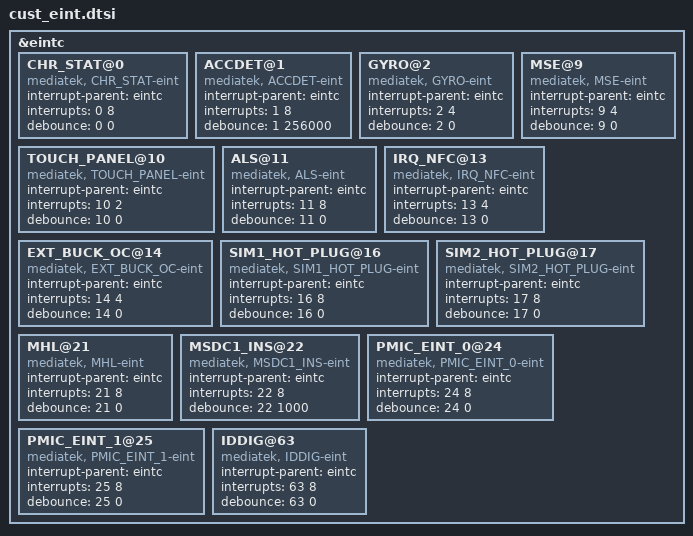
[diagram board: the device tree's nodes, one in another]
/*
 * Generated by MTK SP Drv_CodeGen Version 03.13.6  for MT6752. Copyright MediaTek Inc. (C) 2013.
 * Fri Jul 11 13:05:51 2014
 * Do Not Modify the File.
 */

/*************************
 * EINT DTSI File
*************************/

&eintc {
	CHR_STAT@0 {
		compatible = "mediatek, CHR_STAT-eint";
		interrupt-parent = <&eintc>;
		interrupts = <0 8>;
		debounce = <0 0>;
	};

	ACCDET@1 {
		compatible = "mediatek, ACCDET-eint";
		interrupt-parent = <&eintc>;
		interrupts = <1 8>;
		debounce = <1 256000>;
	};

	GYRO@2 {
		compatible = "mediatek, GYRO-eint";
		interrupt-parent = <&eintc>;
		interrupts = <2 4>;
		debounce = <2 0>;
	};

	MSE@9 {
		compatible = "mediatek, MSE-eint";
		interrupt-parent = <&eintc>;
		interrupts = <9 4>;
		debounce = <9 0>;
	};

	TOUCH_PANEL@10 {
		compatible = "mediatek, TOUCH_PANEL-eint";
		interrupt-parent = <&eintc>;
		interrupts = <10 2>;
		debounce = <10 0>;
	};

	ALS@11 {
		compatible = "mediatek, ALS-eint";
		interrupt-parent = <&eintc>;
		interrupts = <11 8>;
		debounce = <11 0>;
	};

	IRQ_NFC@13 {
		compatible = "mediatek, IRQ_NFC-eint";
		interrupt-parent = <&eintc>;
		interrupts = <13 4>;
		debounce = <13 0>;
	};

	EXT_BUCK_OC@14 {
		compatible = "mediatek, EXT_BUCK_OC-eint";
		interrupt-parent = <&eintc>;
		interrupts = <14 4>;
		debounce = <14 0>;
	};

	SIM1_HOT_PLUG@16 {
		compatible = "mediatek, SIM1_HOT_PLUG-eint";
		interrupt-parent = <&eintc>;
		interrupts = <16 8>;
		debounce = <16 0>;
	};

	SIM2_HOT_PLUG@17 {
		compatible = "mediatek, SIM2_HOT_PLUG-eint";
		interrupt-parent = <&eintc>;
		interrupts = <17 8>;
		debounce = <17 0>;
	};

	MHL@21 {
		compatible = "mediatek, MHL-eint";
		interrupt-parent = <&eintc>;
		interrupts = <21 8>;
		debounce = <21 0>;
	};

	MSDC1_INS@22 {
		compatible = "mediatek, MSDC1_INS-eint";
		interrupt-parent = <&eintc>;
		interrupts = <22 8>;
		debounce = <22 1000>;
	};

	PMIC_EINT_0@24 {
		compatible = "mediatek, PMIC_EINT_0-eint";
		interrupt-parent = <&eintc>;
		interrupts = <24 8>;
		debounce = <24 0>;
	};

	PMIC_EINT_1@25 {
		compatible = "mediatek, PMIC_EINT_1-eint";
		interrupt-parent = <&eintc>;
		interrupts = <25 8>;
		debounce = <25 0>;
	};

	IDDIG@63 {
		compatible = "mediatek, IDDIG-eint";
		interrupt-parent = <&eintc>;
		interrupts = <63 8>;
		debounce = <63 0>;
	};

};
